# nrf52840 register map
Vendor: Nordic Semiconductor; Series: nrf52; File version: 1
CPU: CM4 r0p1, little endian, MPU, FPU, 3 interrupt priority bits
Registers are 32-bit, read-write, reset 0x0 unless marked. A register's access mark holds for its fields unless they carry their own. Offsets are from the block's base; [hi:lo] are bit positions; {n}, {i} and the like mark numbered series; <NAME> marks a mode.

## LPCOMP — Low Power Comparator
Base 0x40013000; alternate view of COMP
0x00 TASKS_START wo — Start comparator
  [0] TASKS_START
0x04 TASKS_STOP wo — Stop comparator
  [0] TASKS_STOP
0x08 TASKS_SAMPLE wo — Sample comparator value
  [0] TASKS_SAMPLE
0x100 EVENTS_READY — LPCOMP is ready and output is valid
  [0] EVENTS_READY
0x104 EVENTS_DOWN — Downward crossing
  [0] EVENTS_DOWN
0x108 EVENTS_UP — Upward crossing
  [0] EVENTS_UP
0x10C EVENTS_CROSS — Downward or upward crossing
  [0] EVENTS_CROSS
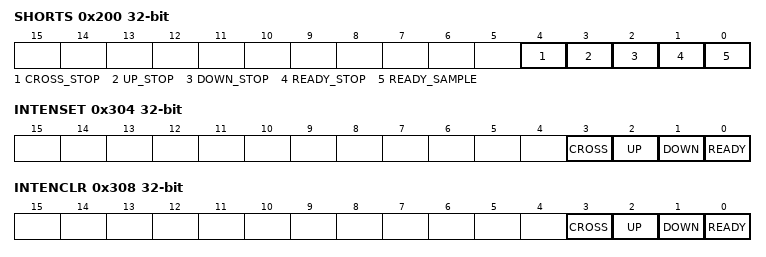
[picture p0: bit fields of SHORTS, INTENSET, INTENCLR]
0x200 SHORTS — Shortcut register
  [all] fields
    0=Disabled (Disable shortcut); 1=Enabled (Enable shortcut)
  [4] CROSS_STOP — Shortcut between CROSS event and STOP task
  [3] UP_STOP — Shortcut between UP event and STOP task
  [2] DOWN_STOP — Shortcut between DOWN event and STOP task
  [1] READY_STOP — Shortcut between READY event and STOP task
  [0] READY_SAMPLE — Shortcut between READY event and SAMPLE task
0x304 INTENSET — Enable interrupt
  [all] fields
    on read: 0=Disabled (Read: Disabled); 1=Enabled (Read: Enabled) | on write: 1=Set (Enable)
  [3] CROSS — Write '1' to enable interrupt for CROSS event
  [2] UP — Write '1' to enable interrupt for UP event
  [1] DOWN — Write '1' to enable interrupt for DOWN event
  [0] READY — Write '1' to enable interrupt for READY event
0x308 INTENCLR — Disable interrupt
  [all] fields
    on read: 0=Disabled (Read: Disabled); 1=Enabled (Read: Enabled) | on write: 1=Clear (Disable)
  [3] CROSS — Write '1' to disable interrupt for CROSS event
  [2] UP — Write '1' to disable interrupt for UP event
  [1] DOWN — Write '1' to disable interrupt for DOWN event
  [0] READY — Write '1' to disable interrupt for READY event
0x400 RESULT ro — Compare result
  [0] RESULT — Result of last compare. Decision point SAMPLE task.
    0=Below (Input voltage is below the reference threshold (VIN+ < VIN-).); 1=Above (Input voltage is above the reference threshold (VIN+ > VIN-).)
0x500 ENABLE — Enable LPCOMP
  [1:0] ENABLE — Enable or disable LPCOMP
    0=Disabled; 1=Enabled
0x504 PSEL — Input pin select
  [2:0] PSEL — Analog pin select
    {v}=AnalogInput{v} (AIN{v} selected as analog input) (v=0..7)
0x508 REFSEL reset 0x4 — Reference select
  [3:0] REFSEL
    {v}=Ref{v+1}_8Vdd (VDD * {v+1}/8 selected as reference) (v=0..6); 7=ARef (External analog reference selected); 8=Ref1_16Vdd (VDD * 1/16 selected as reference); 9=Ref3_16Vdd (VDD * 3/16 selected as reference); 10=Ref5_16Vdd (VDD * 5/16 selected as reference); 11=Ref7_16Vdd (VDD * 7/16 selected as reference); 12=Ref9_16Vdd (VDD * 9/16 selected as reference); 13=Ref11_16Vdd (VDD * 11/16 selected as reference); 14=Ref13_16Vdd (VDD * 13/16 selected as reference); 15=Ref15_16Vdd (VDD * 15/16 selected as reference)
0x50C EXTREFSEL — External reference select
  [0] EXTREFSEL — External analog reference select
    0=AnalogReference0 (Use AIN0 as external analog reference); 1=AnalogReference1 (Use AIN1 as external analog reference)
0x520 ANADETECT — Analog detect configuration
  [1:0] ANADETECT
    0=Cross (Generate ANADETECT on crossing, both upward crossing and downward crossing); 1=Up (Generate ANADETECT on upward crossing only); 2=Down (Generate ANADETECT on downward crossing only)
0x538 HYST — Comparator hysteresis enable
  [0] HYST
    0=Disabled (Comparator hysteresis disabled); 1=Enabled (Comparator hysteresis enabled)

## EGU0 — Event Generator Unit 0
Base 0x40014000
Same registers: EGU1 0x40015000, EGU2 0x40016000, EGU3 0x40017000, EGU4 0x40018000, EGU5 0x40019000
{0x0+4i} TASKS_TRIGGER[{i}] (i=0..15) wo — Description collection[n]: Trigger n for triggering the corresponding TRIGGERED[n] event
  [0] TASKS_TRIGGER
{0x100+4i} EVENTS_TRIGGERED[{i}] (i=0..15) — Description collection[n]: Event number n generated by triggering the corresponding TRIGGER[n] task
  [0] EVENTS_TRIGGERED
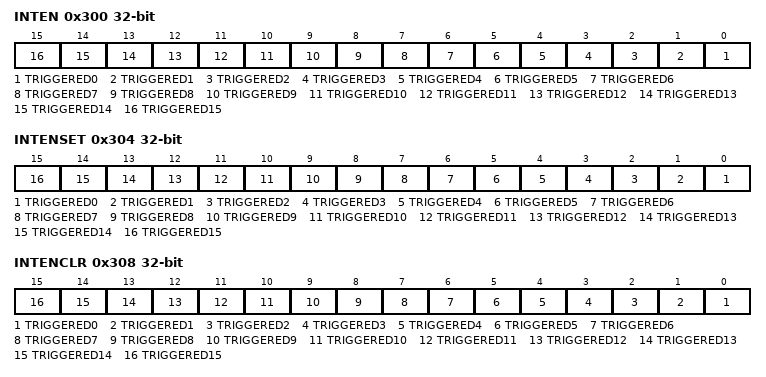
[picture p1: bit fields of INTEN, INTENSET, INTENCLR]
0x300 INTEN — Enable or disable interrupt
  [all] fields
    0=Disabled; 1=Enabled
  [n] TRIGGERED{n} (n=0..15) — Enable or disable interrupt for TRIGGERED[{n}] event
0x304 INTENSET — Enable interrupt
  [all] fields
    on read: 0=Disabled (Read: Disabled); 1=Enabled (Read: Enabled) | on write: 1=Set (Enable)
  [n] TRIGGERED{n} (n=0..15) — Write '1' to enable interrupt for TRIGGERED[{n}] event
0x308 INTENCLR — Disable interrupt
  [all] fields
    on read: 0=Disabled (Read: Disabled); 1=Enabled (Read: Enabled) | on write: 1=Clear (Disable)
  [n] TRIGGERED{n} (n=0..15) — Write '1' to disable interrupt for TRIGGERED[{n}] event
